# PRU_ICSSG1_PR1_ICSS_UART_UART_SLV register map
Vendor: Texas Instruments
Peripheral module from a debugger description file (folder am243x).
Registers are 32-bit, read-write, reset 0x0 unless marked. A register's access mark holds for its fields unless they carry their own. Offsets are as the file gives them; lines under a group give offsets from that group; [hi:lo] are bit positions; {n}, {i} and the like mark numbered series; 'fields as' and 'values as' point back to an identical list; <NAME> marks a mode.

## PRU_ICSSG1_PR1_ICSS_UART_UART_SLV
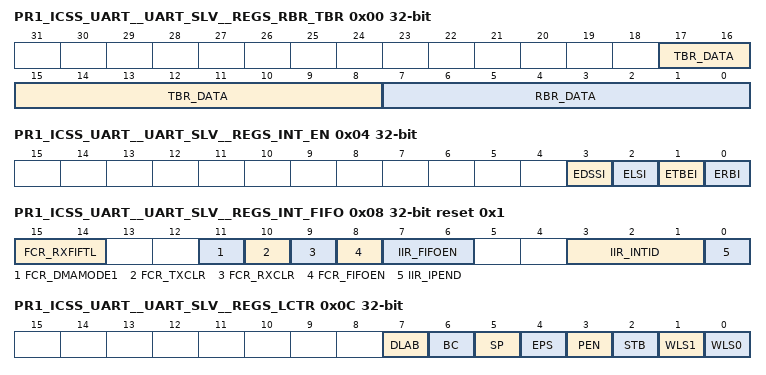
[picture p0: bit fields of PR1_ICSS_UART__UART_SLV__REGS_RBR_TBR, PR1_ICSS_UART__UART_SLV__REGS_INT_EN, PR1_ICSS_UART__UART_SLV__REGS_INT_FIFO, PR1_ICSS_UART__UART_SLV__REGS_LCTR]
0x00 PR1_ICSS_UART__UART_SLV__REGS_RBR_TBR access per field — RBR_TBR Registers
  [17:8] TBR_DATA wo — Transmit Buffer Register
  [7:0] RBR_DATA ro — Receive Buffer Register
0x04 PR1_ICSS_UART__UART_SLV__REGS_INT_EN — UART Interrupt Enable Register
  [3] EDSSI — Enable for Modem Status Interrupt
  [2] ELSI — Enable for Receiver Line Status Interrupt
  [1] ETBEI — Enable for Transmitter Holding Register Empty Interrupt
  [0] ERBI — Enable for Receiver Data Available Interrupt
0x08 PR1_ICSS_UART__UART_SLV__REGS_INT_FIFO access per field reset 0x1 — Interrupt Identification Register / FIFO Control Register
  [15:14] FCR_RXFIFTL wo — Receiver Trigger Level
  [11] FCR_DMAMODE1 wo — DMA Mode Select
  [10] FCR_TXCLR wo — Transmitter FIFO Reset
  [9] FCR_RXCLR wo — Receiver FIFO Reset
  [8] FCR_FIFOEN wo — FIFO Enable Register
  [7:6] IIR_FIFOEN ro — FIFOs enabled
  [3:1] IIR_INTID ro — Interrupt Type
  [0] IIR_IPEND ro — Receiver Data Available Interrupt Pending
0x0C PR1_ICSS_UART__UART_SLV__REGS_LCTR — Line Control Register
  [7] DLAB — Divisor Latch Access Bit
  [6] BC — Break Control
  [5] SP — Stick Parity
  [4] EPS — Even Parity Select
  [3] PEN — Parity Enable
  [2] STB — Number of Stop Bits
  [1] WLS1 — Word Length Select Bit 1
  [0] WLS0 — Word Length Select Bit 0
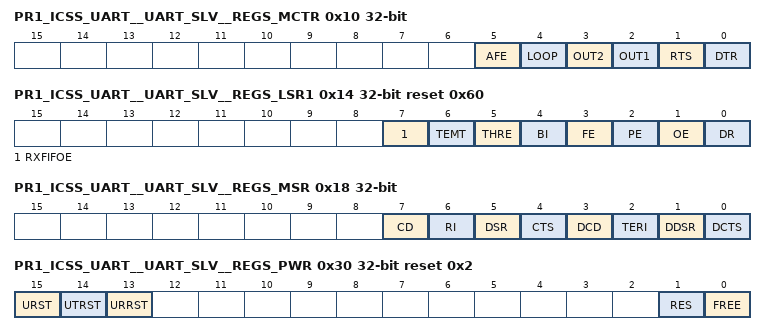
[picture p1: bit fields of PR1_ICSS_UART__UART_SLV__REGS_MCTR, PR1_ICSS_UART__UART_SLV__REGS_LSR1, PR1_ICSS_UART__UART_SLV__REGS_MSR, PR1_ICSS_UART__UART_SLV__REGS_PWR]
0x10 PR1_ICSS_UART__UART_SLV__REGS_MCTR — Modem Control Register
  [5] AFE — Autoflow Control Enable
  [4] LOOP — LOOP Bit
  [3] OUT2 — Out2 Bit
  [2] OUT1 — Out1 Bit
  [1] RTS — Ready to Send
  [0] DTR — Data Terminal Ready
0x14 PR1_ICSS_UART__UART_SLV__REGS_LSR1 ro reset 0x60 — Line Status Register1
  [7] RXFIFOE — Receiver FIFO Error
  [6] TEMT — Transmitter Empty
  [5] THRE — Transmitter Holding Register
  [4] BI — Break Interrupt
  [3] FE — Framing Error
  [2] PE — Parity Error
  [1] OE — Overrun Error
  [0] DR — Data Ready
0x18 PR1_ICSS_UART__UART_SLV__REGS_MSR ro — Modem Status Register
  [7] CD — Carrier Detect
  [6] RI — Ring Indicator
  [5] DSR — Data Set Ready
  [4] CTS — Clear To Send
  [3] DCD — Delta Carrier Detect
  [2] TERI — Trailing Edge Ring Indicator
  [1] DDSR — Delta Set Ready
  [0] DCTS — Delta Clear To Send
0x1C PR1_ICSS_UART__UART_SLV__REGS_SCRATCH — UART Scratch Register
  [7:0] DATA — Scratch Register Bits
0x20 PR1_ICSS_UART__UART_SLV__REGS_DIVLSB — UART Divisor Register
  [7:0] DLL — Divisor Latch [LSB]
0x24 PR1_ICSS_UART__UART_SLV__REGS_DIVMSB — UART Divisor Register
  [7:0] DLH — Divisor Latch [MSB]
0x28 PR1_ICSS_UART__UART_SLV__REGS_PID ro reset 0x44141102 — Peripheral ID Register
0x30 PR1_ICSS_UART__UART_SLV__REGS_PWR access per field reset 0x2 — UART PowerManagement and Emulation Register
  [15] URST rw — UART Reset Bit
  [14] UTRST rw — UART Transmitter Reset Bit
  [13] URRST rw — UART Receiver Reset Bit
  [1] RES ro — Free Bit
  [0] FREE rw — Free Bit
0x34 PR1_ICSS_UART__UART_SLV__REGS_MODE — UART Mode Definition Register
  [0] OSM_SEL — Oversampling Mode Select
